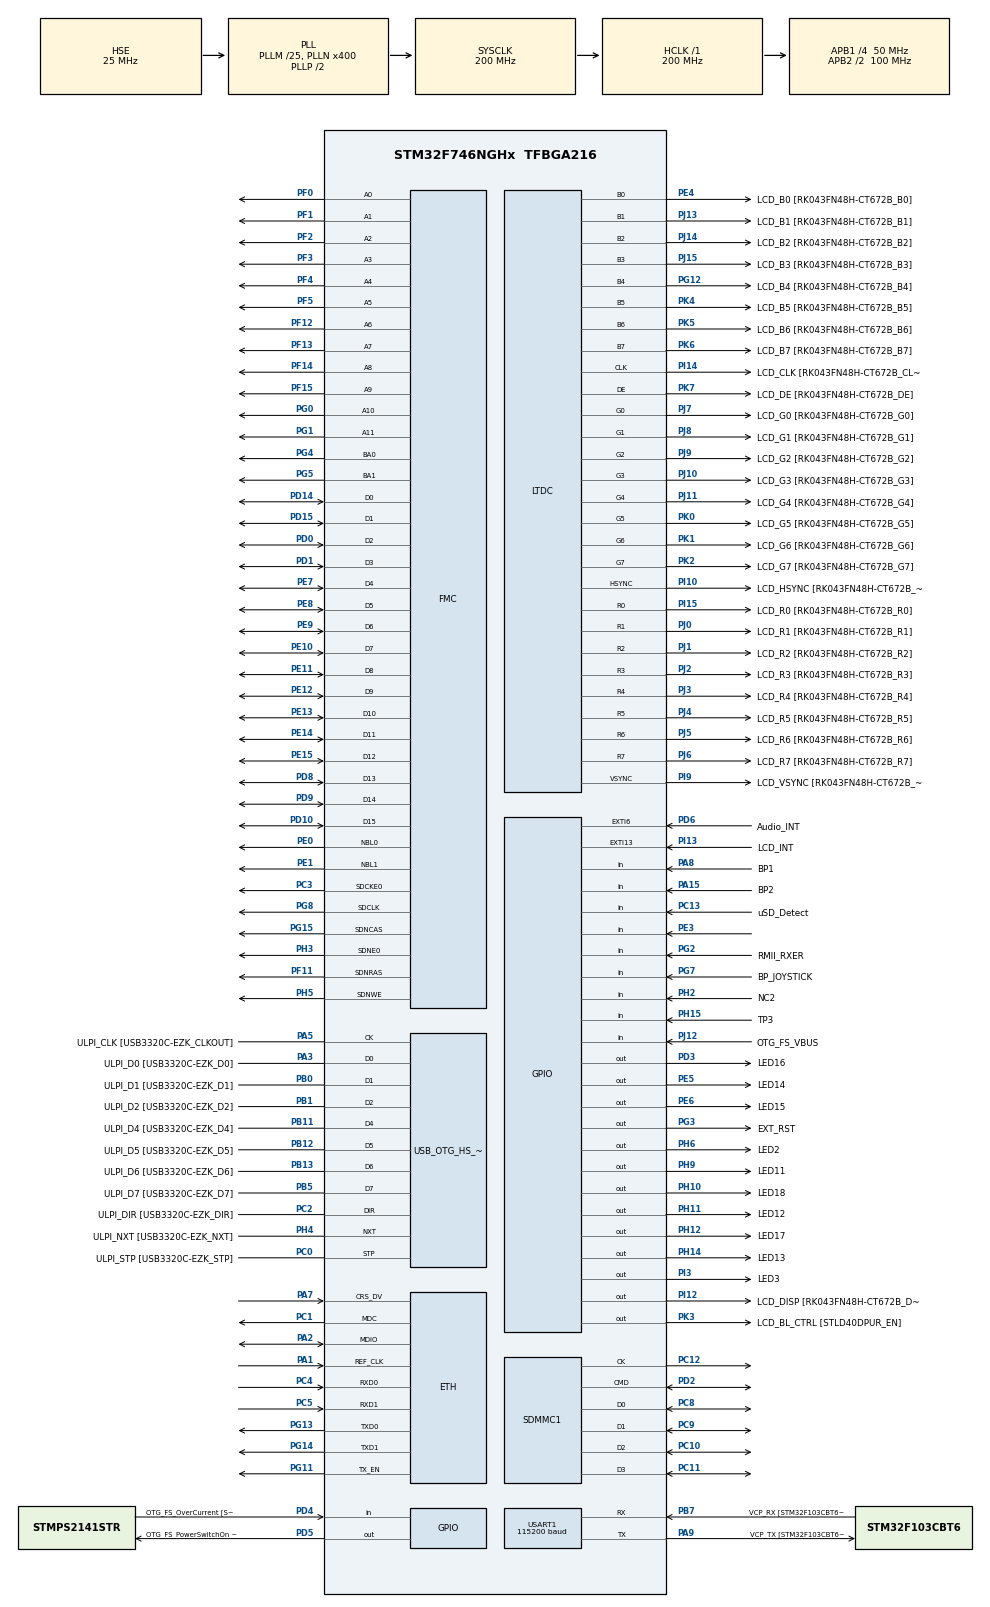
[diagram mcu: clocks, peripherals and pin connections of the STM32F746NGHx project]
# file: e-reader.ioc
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SH.FMC_A0.0=FMC_A0,12b-sda1
FATFS0.BSP.api=Unknown
PH15.GPIO_Label=TP3
NVIC.TIM6_DAC_IRQn=true\:0\:0\:false\:false\:true\:false\:false\:true
PG8.Signal=FMC_SDCLK
PG0.Signal=FMC_A10
PI15.GPIO_Label=LCD_R0 [RK043FN48H-CT672B_R0]
PK1.Signal=LTDC_G6
SH.FMC_D5_DA5.0=FMC_D5,sd-16b-d1
SH.FMC_D9_DA9.0=FMC_D9,sd-16b-d1
PF7.Signal=UART7_TX
RCC.PLL48CLockSelection=RCC_CLK48SOURCE_PLLSAIP
SH.FMC_SDNWE.0=FMC_SDNWE,12b-sda1
PH9.Signal=GPIO_Output
SH.FMC_D11_DA11.0=FMC_D11,sd-16b-d1
PJ5.Mode=RGB888
RCC.APB2TimFreq_Value=200000000
PC7.Signal=USART6_RX
PD0.Signal=FMC_D2_DA2
PD8.Signal=FMC_D13_DA13
PE1.Signal=FMC_NBL1
FATFS0.BSP.ip=GPIO
PK4.GPIO_Label=LCD_B5 [RK043FN48H-CT672B_B5]
PB12.GPIO_Label=ULPI_D5 [USB3320C-EZK_D5]
PJ14.Mode=RGB888
PG14.Mode=RMII
LTDC.PixelFormat_L0=LTDC_PIXEL_FORMAT_RGB565
PE9.Signal=FMC_D6_DA6
SH.FMC_A2.0=FMC_A2,12b-sda1
PB1.GPIO_Label=ULPI_D2 [USB3320C-EZK_D2]
PE4.GPIO_Label=LCD_B0 [RK043FN48H-CT672B_B0]
PC9.Mode=SD_4_bits_Wide_bus
PA8.Signal=GPIO_Input
SH.FMC_D1_DA1.0=FMC_D1,sd-16b-d1
VP_FREERTOS_VS_CMSIS_V1.Mode=CMSIS_V1
LTDC.HSync=41
PJ14.Signal=LTDC_B2
PB9.Signal=I2C1_SDA
Mcu.Package=TFBGA216
PB1.Signal=USB_OTG_HS_ULPI_D2
NVIC.TimeBase=TIM6_DAC_IRQn
NVIC.TimeBaseIP=TIM6
PB9.GPIO_PuPd=GPIO_NOPULL
PC11.Mode=SD_4_bits_Wide_bus
RCC.APB2CLKDivider=RCC_HCLK_DIV2
LTDC.VSync=10
RCC.APB1TimFreq_Value=100000000
PC14/OSC32_IN.GPIO_Label=RCC_OSC32_IN
PB13.Mode=Host_HS
PJ13.Mode=RGB888
Dma.SDMMC1_RX.0.Mode=DMA_PFCTRL
PD15.Signal=FMC_D1_DA1
PJ1.GPIO_Label=LCD_R2 [RK043FN48H-CT672B_R2]
PG12.Signal=LTDC_B4
PA5.Mode=Host_HS
FATFS0.BSP.STBoard=false
PK4.Signal=LTDC_B5
SH.FMC_A4.0=FMC_A4,12b-sda1
FREERTOS.Tasks01=defaultTask,0,1024,StartDefaultTask,Default,NULL,Dynamic,NULL,NULL;displayer_task,0,2048,displayer_task_fn,Default,NULL,Dynamic,NULL,NULL;logic_task,1,1024,logic_task_fn,Default,NULL,Dynamic,NULL,NULL
Dma.SDMMC1_RX.0.PeriphInc=DMA_PINC_DISABLE
PI13.GPIO_ModeDefaultEXTI=GPIO_MODE_EVT_RISING
PG5.Signal=FMC_A15_BA1
PC13.Signal=GPIO_Input
SH.FMC_D10_DA10.0=FMC_D10,sd-16b-d1
FATFS0.BSP.mode=Input
FREERTOS.INCLUDE_vTaskDelayUntil=1
PD3.Signal=GPIO_Output
PI10.Mode=RGB888
PC2.Signal=USB_OTG_HS_ULPI_DIR
PI12.Signal=GPIO_Output
PJ11.Signal=LTDC_G4
RCC.PLLSAIRDiv=RCC_PLLSAIDIVR_8
LTDC.ImageWidth_L0=480
PD10.Signal=FMC_D15_DA15
PJ6.Mode=RGB888
PA3.Mode=Host_HS
PB8.GPIO_Label=ARDUINO SCL/D15
PJ8.GPIO_Label=LCD_G1 [RK043FN48H-CT672B_G1]
PJ3.Signal=LTDC_R4
PI8.GPIO_Label=NC1 [TP2]
PA8.GPIO_Label=BP1
PH11.GPIO_Label=LED12
LWIP.CHECKSUM_GEN_TCP=1
NVIC.DMA2_Stream6_IRQn=true\:5\:0\:false\:false\:true\:true\:false\:true
PJ11.GPIO_Label=LCD_G4 [RK043FN48H-CT672B_G4]
PB14.Signal=SPI2_MISO
PA5.Signal=USB_OTG_HS_ULPI_CK
PC12.Mode=SD_4_bits_Wide_bus
PJ4.GPIO_Label=LCD_R5 [RK043FN48H-CT672B_R5]
PK7.GPIO_Label=LCD_DE [RK043FN48H-CT672B_DE]
SH.FMC_A6.0=FMC_A6,12b-sda1
PE14.Signal=FMC_D11_DA11
PG7.GPIO_Label=BP_JOYSTICK
PI2.Signal=S_TIM8_CH4
PF13.Signal=FMC_A7
PJ15.GPIO_Label=LCD_B3 [RK043FN48H-CT672B_B3]
PC8.Mode=SD_4_bits_Wide_bus
PJ15.Mode=RGB888
ETH.MediaInterface=ETH_MEDIA_INTERFACE_RMII
PA5.GPIO_Label=ULPI_CLK [USB3320C-EZK_CLKOUT]
PK4.Mode=RGB888
PE5.GPIO_Label=LED14
Dma.SDMMC1_TX.1.PeriphDataAlignment=DMA_PDATAALIGN_WORD
PJ8.Signal=LTDC_G1
PJ0.GPIO_Label=LCD_R1 [RK043FN48H-CT672B_R1]
ProjectManager.HeapSize=0x400
PB1.Mode=Host_HS
PH6.Signal=GPIO_Output
FREERTOS.configUSE_RECURSIVE_MUTEXES=1
NVIC.PriorityGroup=NVIC_PRIORITYGROUP_4
PI1.GPIO_Mode=GPIO_MODE_AF_PP
PE3.Signal=GPIO_Input
PJ4.Mode=RGB888
PC15/OSC32_OUT.Signal=RCC_OSC32_OUT
PF4.Signal=FMC_A4
PD2.Signal=SDMMC1_CMD
FATFS0.BSP.name=Detect_SDIO
PC1.Mode=RMII
PI1.GPIO_Label=ARDUINO SCK/D13
Mcu.Family=STM32F7
LTDC.BlendingFactor1_L0=LTDC_BLENDING_FACTOR1_PAxCA
PK3.Signal=GPIO_Output
SH.FMC_A8.0=FMC_A8,12b-sda1
PC15/OSC32_OUT.GPIO_Label=RCC_OSC32_OUT
PH14.Signal=GPIO_Output
PH10.Signal=GPIO_Output
SH.FMC_D14_DA14.0=FMC_D14,sd-16b-d1
PG2.Signal=GPIO_Input
USART1.BaudRate=115200
PC14/OSC32_IN.Mode=LSE-External-Oscillator
SH.FMC_A14_BA0.0=FMC_BA0,FourSdramBanks1
SH.FMC_A11.0=FMC_A11,12b-sda1
Dma.SDMMC1_RX.0.Instance=DMA2_Stream3
Dma.SDMMC1_RX.0.FIFOMode=DMA_FIFOMODE_ENABLE
PB13.GPIO_Label=ULPI_D6 [USB3320C-EZK_D6]
PB15.Signal=SPI2_MOSI
PG15.Signal=FMC_SDNCAS
PG11.Signal=ETH_TX_EN
PJ5.GPIO_Label=LCD_R6 [RK043FN48H-CT672B_R6]
PJ14.GPIO_Label=LCD_B2 [RK043FN48H-CT672B_B2]
PA15.GPIO_Label=BP2
PJ2.Signal=LTDC_R3
SH.FMC_NBL1.0=FMC_NBL1,Sd2ByteEnable1
LTDC.WindowX1_L0=480
PI9.Mode=RGB888
PK2.Mode=RGB888
PA9.GPIO_Mode=GPIO_MODE_AF_PP
RCC.HSE_VALUE=25000000
LWIP.CHECKSUM_CHECK_TCP=1
PI14.Mode=RGB888
PA14.Mode=Serial_Wire
PH7.GPIO_Label=LCD_SCL [RK043FN48H-CT672B_SCL]
PJ7.GPIO_Label=LCD_G0 [RK043FN48H-CT672B_G0]
PF11.Signal=FMC_SDNRAS
PB5.Mode=Host_HS
ETH.RxMode=ETH_RXINTERRUPT_MODE
PJ12.GPIO_Label=OTG_FS_VBUS
PB7.Signal=USART1_RX
SH.S_TIM3_CH1.0=TIM3_CH1
PB7.GPIO_Label=VCP_RX [STM32F103CBT6_PA2]
PB12.Mode=Host_HS
LWIP.CHECKSUM_CHECK_IP=1
PD5.GPIO_Label=OTG_FS_PowerSwitchOn [STMPS2141STR_EN]
PA15.Signal=GPIO_Input
PF8.Signal=ADC3_IN6
PB5.GPIO_Label=ULPI_D7 [USB3320C-EZK_D7]
Dma.Request1=SDMMC1_TX
PD3.GPIO_Label=LED16
PC5.Signal=ETH_RXD1
PE7.Signal=FMC_D4_DA4
PD6.Signal=GPXTI6
Dma.Request0=SDMMC1_RX
Dma.SDMMC1_RX.0.MemDataAlignment=DMA_MDATAALIGN_WORD
PI15.Mode=RGB888
PB4.Signal=S_TIM3_CH1
PG2.GPIO_Label=RMII_RXER
PA3.Signal=USB_OTG_HS_ULPI_D0
PK1.Mode=RGB888
PK6.Signal=LTDC_B7
NVIC.LTDC_IRQn=true\:5\:0\:false\:false\:true\:true\:true\:true
LTDC.WindowY1_L0=272
PG7.Signal=GPIO_Input
PJ8.Mode=RGB888
PH12.GPIO_Label=LED17
PC11.Signal=SDMMC1_D3
PI14.Signal=LTDC_CLK
PC8.Signal=SDMMC1_D0
PC10.Mode=SD_4_bits_Wide_bus
PC2.Mode=Host_HS
PD9.Signal=FMC_D14_DA14
PA9.GPIO_PuPd=GPIO_NOPULL
FATFS0.BSP.instance=PC13
USART1.VirtualMode-Asynchronous=VM_ASYNC
PA13.Signal=SYS_JTMS-SWDIO
FREERTOS.configUSE_IDLE_HOOK=1
PA9.Mode=Asynchronous
SH.FMC_D13_DA13.0=FMC_D13,sd-16b-d1
PH8.Signal=I2C3_SDA
RCC.USBFreq_Value=48000000
PA1.Signal=ETH_REF_CLK
PD2.Mode=SD_4_bits_Wide_bus
PK5.Mode=RGB888
board=STM32F746G-DISCO
PG12.Mode=RGB888
RCC.VCOOutputFreq_Value=400000000
PI9.Signal=LTDC_VSYNC
PH4.GPIO_Label=ULPI_NXT [USB3320C-EZK_NXT]
PI13.GPIO_Label=LCD_INT
SH.FMC_D12_DA12.0=FMC_D12,sd-16b-d1
Dma.SDMMC1_RX.0.MemBurst=DMA_MBURST_INC4
PI1.GPIO_Speed=GPIO_SPEED_FREQ_LOW
PF1.Signal=FMC_A1
PJ0.Signal=LTDC_R1
PE0.Signal=FMC_NBL0
PE12.Signal=FMC_D9_DA9
RCC.SYSCLKFreq_VALUE=200000000
Dma.SDMMC1_TX.1.MemBurst=DMA_MBURST_INC4
PJ5.Signal=LTDC_R6
RCC.HSI_VALUE=16000000
PH0/OSC_IN.GPIO_Label=OSC_25M [NZ2520SB-25.00M_OUT]
RCC.PLLQ=9
PI3.GPIO_Label=LED3
PH3.Signal=FMC_SDNE0
RCC.PLLM=25
RCC.PLLN=400
PA9.GPIO_Speed=GPIO_SPEED_FREQ_LOW
PA2.Mode=RMII
PB8.GPIO_Speed=GPIO_SPEED_FREQ_LOW
PJ2.GPIO_Label=LCD_R3 [RK043FN48H-CT672B_R3]
VP_CRC_VS_CRC.Mode=CRC_Activate
LTDC.ImageHeight_L0=272
Dma.SDMMC1_TX.1.PeriphInc=DMA_PINC_DISABLE
RCC.PLLI2SN=100
PB12.Signal=USB_OTG_HS_ULPI_D5
PK1.GPIO_Label=LCD_G6 [RK043FN48H-CT672B_G6]
PJ13.Signal=LTDC_B1
PA3.GPIO_Label=ULPI_D0 [USB3320C-EZK_D0]
PI12.PinState=GPIO_PIN_SET
SH.FMC_D7_DA7.0=FMC_D7,sd-16b-d1
PK5.Signal=LTDC_B6
VP_SYS_VS_tim6.Mode=TIM6
PJ9.Mode=RGB888
PH12.Signal=GPIO_Output
Dma.SDMMC1_RX.0.MemInc=DMA_MINC_ENABLE
VP_FATFS_VS_SDIO.Mode=SDIO
PK0.Mode=RGB888
PG4.Signal=FMC_A14_BA0
PC12.Signal=SDMMC1_CK
PA14.GPIO_Label=SWCLK
PH6.GPIO_Label=LED2
PK6.GPIO_Label=LCD_B7 [RK043FN48H-CT672B_B7]
PJ6.GPIO_Label=LCD_R7 [RK043FN48H-CT672B_R7]
PC5.Mode=RMII
PB13.Signal=USB_OTG_HS_ULPI_D6
PD6.GPIO_Label=Audio_INT
PG13.Signal=ETH_TXD0
PE6.GPIO_Label=LED15
RCC.SYSCLKSource=RCC_SYSCLKSOURCE_PLLCLK
PJ10.Signal=LTDC_G3
SH.FMC_A15_BA1.0=FMC_BA1,FourSdramBanks1
LWIP.NETMASK_ADDRESS=255.255.255.000
NVIC.SDMMC1_IRQn=true\:5\:0\:false\:false\:true\:true\:true\:true
PB7.GPIO_Mode=GPIO_MODE_AF_PP
PJ13.GPIO_Label=LCD_B1 [RK043FN48H-CT672B_B1]
PH5.Signal=FMC_SDNWE
LWIP.CHECKSUM_GEN_IP=1
PD4.Signal=GPIO_Input
PH1/OSC_OUT.Signal=RCC_OSC_OUT
PC3.Signal=FMC_SDCKE0
PE5.Signal=GPIO_Output
PH10.GPIO_Label=LED18
FATFS0.BSP.i2caddr=0
PK7.Mode=RGB888
PJ2.Mode=RGB888
PI3.Signal=GPIO_Output
PF3.Signal=FMC_A3
PE10.Signal=FMC_D7_DA7
RCC.SDMMCClockSelection=RCC_SDMMC1CLKSOURCE_CLK48
SH.S_TIM8_CH4.0=TIM8_CH4
PD6.GPIO_ModeDefaultEXTI=GPIO_MODE_EVT_RISING
FATFS0.BSP.solution=PC13
Dma.SDMMC1_RX.0.PeriphBurst=DMA_PBURST_INC4
PJ4.Signal=LTDC_R5
SH.FMC_A1.0=FMC_A1,12b-sda1
PH2.Signal=GPIO_Input
SH.FMC_SDCLK.0=FMC_SDCLK,12b-sda1
PF14.Signal=FMC_A8
VP_DMA2D_VS_DMA2D.Mode=DMA2D_Activate
Dma.SDMMC1_TX.1.MemInc=DMA_MINC_ENABLE
PJ1.Mode=RGB888
SH.FMC_D3_DA3.0=FMC_D3,sd-16b-d1
PC4.Mode=RMII
LWIP.IP_ADDRESS=192.168.137.101
PI10.GPIO_Label=LCD_HSYNC [RK043FN48H-CT672B_HSYNC]
PB7.GPIO_PuPd=GPIO_NOPULL
Dma.SDMMC1_TX.1.Instance=DMA2_Stream6
PK3.PinState=GPIO_PIN_SET
PH15.Signal=GPIO_Input
PA9.GPIO_Label=VCP_TX [STM32F103CBT6_PA3]
FREERTOS.configCHECK_FOR_STACK_OVERFLOW=2
PB8.GPIO_PuPd=GPIO_NOPULL
PC6.Signal=USART6_TX
ETH.MACAddr=00\:80\:E1\:E0\:00\:00
PB11.GPIO_Label=ULPI_D4 [USB3320C-EZK_D4]
PD1.Signal=FMC_D3_DA3
Dma.SDMMC1_RX.0.PeriphDataAlignment=DMA_PDATAALIGN_WORD
LWIP.LWIP_DHCP=0
PC0.Signal=USB_OTG_HS_ULPI_STP
RCC.APB1CLKDivider=RCC_HCLK_DIV4
SH.FMC_A3.0=FMC_A3,12b-sda1
PJ7.Signal=LTDC_G0
PB11.Mode=Host_HS
SH.FMC_D15_DA15.0=FMC_D15,sd-16b-d1
PA9.Signal=USART1_TX
FATFS.BSP.number=1
PJ15.Signal=LTDC_B3
PH9.GPIO_Label=LED11
PI9.GPIO_Label=LCD_VSYNC [RK043FN48H-CT672B_VSYNC]
PA1.Mode=RMII
PE15.Signal=FMC_D12_DA12
PE8.Signal=FMC_D5_DA5
PI1.Signal=SPI2_SCK
Dma.SDMMC1_RX.0.Direction=DMA_PERIPH_TO_MEMORY
Dma.SDMMC1_TX.1.FIFOMode=DMA_FIFOMODE_ENABLE
SH.FMC_SDNCAS.0=FMC_SDNCAS,12b-sda1
PA13.Mode=Serial_Wire
PH4.Mode=Host_HS
PH14.GPIO_Label=LED13
PA4.Signal=COMP_DAC1_group
PB5.Signal=USB_OTG_HS_ULPI_D7
FREERTOS.configUSE_COUNTING_SEMAPHORES=1
PG11.Mode=RMII
SH.FMC_A5.0=FMC_A5,12b-sda1
LTDC.Alpha_L0=255
PK3.GPIO_Label=LCD_BL_CTRL [STLD40DPUR_EN]
LWIP.Version=v2.1.2_Cube
PF9.Signal=ADC3_IN7
PJ10.Mode=RGB888
PG3.GPIO_Label=EXT_RST
PB0.Signal=USB_OTG_HS_ULPI_D1
PC1.Signal=ETH_MDC
PH2.GPIO_Label=NC2
PC3.Mode=SdramChipSelect1_1
PK7.Signal=LTDC_DE
RCC.CortexFreq_Value=200000000
LTDC.HBP=13
PC10.Signal=SDMMC1_D2
SH.FMC_NBL0.0=FMC_NBL0,Sd2ByteEnable1
PC0.GPIO_Label=ULPI_STP [USB3320C-EZK_STP]
SH.FMC_D6_DA6.0=FMC_D6,sd-16b-d1
PA0/WKUP.Signal=ADCx_IN0
PB0.GPIO_Label=ULPI_D1 [USB3320C-EZK_D1]
Dma.SDMMC1_RX.0.Priority=DMA_PRIORITY_LOW
PC13.GPIO_Label=uSD_Detect
PK5.GPIO_Label=LCD_B6 [RK043FN48H-CT672B_B6]
PB11.Signal=USB_OTG_HS_ULPI_D4
PI14.GPIO_Label=LCD_CLK [RK043FN48H-CT672B_CLK]
ProjectManager.StackSize=0x800
PH3.Mode=SdramChipSelect1_1
Dma.SDMMC1_TX.1.FIFOThreshold=DMA_FIFO_THRESHOLD_FULL
PJ6.Signal=LTDC_R7
SH.FMC_A7.0=FMC_A7,12b-sda1
PH0/OSC_IN.Mode=HSE-External-Oscillator
RCC.HCLKFreq_Value=200000000
PF12.Signal=FMC_A6
FREERTOS.configUSE_MALLOC_FAILED_HOOK=1
PI13.Signal=GPXTI13
SH.FMC_A10.0=FMC_A10,12b-sda1
RCC.AHBFreq_Value=200000000
NVIC.ETH_IRQn=true\:5\:0\:false\:false\:true\:true\:false\:true
SH.FMC_D8_DA8.0=FMC_D8,sd-16b-d1
PI8.Signal=RTC_TS
SH.FMC_D2_DA2.0=FMC_D2,sd-16b-d1
PE13.Signal=FMC_D10_DA10
PI1.GPIO_PuPd=GPIO_NOPULL
PK6.Mode=RGB888
PI0.Signal=SPI2_NSS
LTDC.HFP=32
LTDC.BlendingFactor2_L0=LTDC_BLENDING_FACTOR2_PAxCA
PG13.Mode=RMII
SH.ADCx_IN0.0=ADC1_IN0
PE4.Mode=RGB888
SH.FMC_SDNRAS.0=FMC_SDNRAS,12b-sda1
LTDC.ActiveW=480
PE4.Signal=LTDC_B0
PH1/OSC_OUT.Mode=HSE-External-Oscillator
FREERTOS.configTOTAL_HEAP_SIZE=32768
PJ0.Mode=RGB888
PJ9.Signal=LTDC_G2
SH.FMC_D0_DA0.0=FMC_D0,sd-16b-d1
PJ12.Signal=GPIO_Input
PC14/OSC32_IN.Signal=RCC_OSC32_IN
PK0.GPIO_Label=LCD_G5 [RK043FN48H-CT672B_G5]
SH.FMC_A9.0=FMC_A9,12b-sda1
PJ1.Signal=LTDC_R2
SH.FMC_D4_DA4.0=FMC_D4,sd-16b-d1
PI12.GPIO_Label=LCD_DISP [RK043FN48H-CT672B_DISP] 
RCC.PLLSAIN=384
PF5.Signal=FMC_A5
RCC.PLLSAIP=RCC_PLLSAIP_DIV8
RCC.PLLSAIR=5
PH7.Signal=I2C3_SCL
PB9.GPIO_Speed=GPIO_SPEED_FREQ_LOW
PJ3.GPIO_Label=LCD_R4 [RK043FN48H-CT672B_R4]
PK2.GPIO_Label=LCD_G7 [RK043FN48H-CT672B_G7]
PJ7.Mode=RGB888
PF0.Signal=FMC_A0
PC2.GPIO_Label=ULPI_DIR [USB3320C-EZK_DIR]
Dma.SDMMC1_TX.1.Direction=DMA_MEMORY_TO_PERIPH
PB7.GPIO_Speed=GPIO_SPEED_FREQ_LOW
RCC.PLLSourceVirtual=RCC_PLLSOURCE_HSE
SH.COMP_DAC1_group.0=DAC_OUT1
PK2.Signal=LTDC_G7
LTDC.FBStartAdress_L0=0xC0000000
PA7.Mode=RMII
PB9.GPIO_Label=ARDUINO SDA/D14
PH11.Signal=GPIO_Output
PG3.Signal=GPIO_Output
PG1.Signal=FMC_A11
PC4.Signal=ETH_RXD0
PI10.Signal=LTDC_HSYNC
PD5.Signal=GPIO_Output
FREERTOS.configUSE_APPLICATION_TASK_TAG=1
ETH.PhyAddress=0
VP_LWIP_VS_Enabled.Mode=Enabled
LWIP.GATEWAY_ADDRESS=192.168.137.001
PC0.Mode=Host_HS
PJ11.Mode=RGB888
PH8.GPIO_Label=LCD_SDA [RK043FN48H-CT672B_SDA]
Dma.SDMMC1_TX.1.PeriphBurst=DMA_PBURST_INC4
PH4.Signal=USB_OTG_HS_ULPI_NXT
ProjectManager.TargetToolchain=STM32CubeIDE
LTDC.ActiveH=272
PJ9.GPIO_Label=LCD_G2 [RK043FN48H-CT672B_G2]
PF2.Signal=FMC_A2
NVIC.DMA2_Stream3_IRQn=true\:5\:0\:false\:false\:true\:true\:false\:true
PE11.Signal=FMC_D8_DA8
PK0.Signal=LTDC_G5
PG14.Signal=ETH_TXD1
PJ10.GPIO_Label=LCD_G3 [RK043FN48H-CT672B_G3]
PB0.Mode=Host_HS
PB9.GPIO_Mode=GPIO_MODE_AF_OD
PJ3.Mode=RGB888
PH0/OSC_IN.Signal=RCC_OSC_IN
RCC.APB2Freq_Value=100000000
LTDC.Layers=0
PD4.GPIO_Label=OTG_FS_OverCurrent [STMPS2141STR_Fault]
PF10.Signal=ADC3_IN8
PF15.Signal=FMC_A9
Dma.SDMMC1_TX.1.Priority=DMA_PRIORITY_LOW
PD5.PinState=GPIO_PIN_SET
PE6.Signal=GPIO_Output
Mcu.Name=STM32F746NGHx
PA13.GPIO_Label=SWDIO
PA2.Signal=ETH_MDIO
PD14.Signal=FMC_D0_DA0
Dma.SDMMC1_RX.0.FIFOThreshold=DMA_FIFO_THRESHOLD_FULL
PC15/OSC32_OUT.Mode=LSE-External-Oscillator
PB7.Mode=Asynchronous
PA14.Signal=SYS_JTCK-SWCLK
PG12.GPIO_Label=LCD_B4 [RK043FN48H-CT672B_B4]
Dma.SDMMC1_TX.1.MemDataAlignment=DMA_MDATAALIGN_WORD
PK3.GPIO_Speed=GPIO_SPEED_FREQ_LOW
PI15.Signal=LTDC_R0
PB8.Signal=I2C1_SCL
PC9.Signal=SDMMC1_D1
PB8.GPIO_Mode=GPIO_MODE_AF_OD
RCC.APB1Freq_Value=50000000
Dma.SDMMC1_TX.1.Mode=DMA_PFCTRL
PA7.Signal=ETH_CRS_DV

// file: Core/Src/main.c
/* USER CODE BEGIN Header */
/**
  ******************************************************************************
  * @file           : main.c
  * @brief          : Main program body
  ******************************************************************************
  * @attention
  *
  * <h2><center>&copy; Copyright (c) 2021 STMicroelectronics.
  * All rights reserved.</center></h2>
  *
  * This software component is licensed by ST under Ultimate Liberty license
  * SLA0044, the "License"; You may not use this file except in compliance with
  * the License. You may obtain a copy of the License at:
  *                             www.st.com/SLA0044
  *
  ******************************************************************************
  */
/* USER CODE END Header */
#include "main.h"
#include "cmsis_os.h"
#include "fatfs.h"
#include "lwip.h"

/* USER CODE BEGIN Includes */

#include "global.h"

/* USER CODE END Includes */

CRC_HandleTypeDef hcrc;

DMA2D_HandleTypeDef hdma2d;

LTDC_HandleTypeDef hltdc;

SD_HandleTypeDef hsd1;
DMA_HandleTypeDef hdma_sdmmc1_rx;
DMA_HandleTypeDef hdma_sdmmc1_tx;

UART_HandleTypeDef huart1;

SDRAM_HandleTypeDef hsdram1;

osThreadId defaultTaskHandle;
osThreadId displayer_taskHandle;
osThreadId logic_taskHandle;

void SystemClock_Config(void);
static void MX_GPIO_Init(void);
static void MX_DMA_Init(void);
static void MX_LTDC_Init(void);
static void MX_USART1_UART_Init(void);
static void MX_FMC_Init(void);
static void MX_DMA2D_Init(void);
static void MX_CRC_Init(void);
static void MX_SDMMC1_SD_Init(void);
void StartDefaultTask(void const * argument);
void displayer_task_fn(void const * argument);
void logic_task_fn(void const * argument);

int main(void)
{

  /* MCU Configuration--------------------------------------------------------*/

  /* Reset of all peripherals, Initializes the Flash interface and the Systick. */
  HAL_Init();

  /* Configure the system clock */
  SystemClock_Config();

  /* Initialize all configured peripherals */
  MX_GPIO_Init();
  MX_DMA_Init();
  MX_LTDC_Init();
  MX_USART1_UART_Init();
  MX_FMC_Init();
  MX_DMA2D_Init();
  MX_CRC_Init();
  MX_SDMMC1_SD_Init();
  MX_FATFS_Init();

  /* Create the thread(s) */
  /* definition and creation of defaultTask */
  osThreadDef(defaultTask, StartDefaultTask, osPriorityNormal, 0, 1024);
  defaultTaskHandle = osThreadCreate(osThread(defaultTask), NULL);

  /* definition and creation of displayer_task */
  osThreadDef(displayer_task, displayer_task_fn, osPriorityNormal, 0, 2048);
  displayer_taskHandle = osThreadCreate(osThread(displayer_task), NULL);

  /* definition and creation of logic_task */
  osThreadDef(logic_task, logic_task_fn, osPriorityAboveNormal, 0, 1024);
  logic_taskHandle = osThreadCreate(osThread(logic_task), NULL);

  /* Start scheduler */
  osKernelStart();

  /* We should never get here as control is now taken by the scheduler */
  /* Infinite loop */
  while (1)
  {

  }
}

void SystemClock_Config(void)
{
  RCC_OscInitTypeDef RCC_OscInitStruct = {0};
  RCC_ClkInitTypeDef RCC_ClkInitStruct = {0};
  RCC_PeriphCLKInitTypeDef PeriphClkInitStruct = {0};

  /** Configure LSE Drive Capability
  */
  HAL_PWR_EnableBkUpAccess();
  /** Configure the main internal regulator output voltage
  */
  __HAL_RCC_PWR_CLK_ENABLE();
  __HAL_PWR_VOLTAGESCALING_CONFIG(PWR_REGULATOR_VOLTAGE_SCALE1);
  /** Initializes the RCC Oscillators according to the specified parameters
  * in the RCC_OscInitTypeDef structure.
  */
  RCC_OscInitStruct.OscillatorType = RCC_OSCILLATORTYPE_HSE;
  RCC_OscInitStruct.HSEState = RCC_HSE_ON;
  RCC_OscInitStruct.PLL.PLLState = RCC_PLL_ON;
  RCC_OscInitStruct.PLL.PLLSource = RCC_PLLSOURCE_HSE;
  RCC_OscInitStruct.PLL.PLLM = 25;
  RCC_OscInitStruct.PLL.PLLN = 400;
  RCC_OscInitStruct.PLL.PLLP = RCC_PLLP_DIV2;
  RCC_OscInitStruct.PLL.PLLQ = 9;
  if (HAL_RCC_OscConfig(&RCC_OscInitStruct) != HAL_OK)
  {
    Error_Handler();
  }
  /** Activate the Over-Drive mode
  */
  if (HAL_PWREx_EnableOverDrive() != HAL_OK)
  {
    Error_Handler();
  }
  /** Initializes the CPU, AHB and APB buses clocks
  */
  RCC_ClkInitStruct.ClockType = RCC_CLOCKTYPE_HCLK|RCC_CLOCKTYPE_SYSCLK
                              |RCC_CLOCKTYPE_PCLK1|RCC_CLOCKTYPE_PCLK2;
  RCC_ClkInitStruct.SYSCLKSource = RCC_SYSCLKSOURCE_PLLCLK;
  RCC_ClkInitStruct.AHBCLKDivider = RCC_SYSCLK_DIV1;
  RCC_ClkInitStruct.APB1CLKDivider = RCC_HCLK_DIV4;
  RCC_ClkInitStruct.APB2CLKDivider = RCC_HCLK_DIV2;

  if (HAL_RCC_ClockConfig(&RCC_ClkInitStruct, FLASH_LATENCY_6) != HAL_OK)
  {
    Error_Handler();
  }
  PeriphClkInitStruct.PeriphClockSelection = RCC_PERIPHCLK_LTDC|RCC_PERIPHCLK_USART1
                              |RCC_PERIPHCLK_SDMMC1|RCC_PERIPHCLK_CLK48;
  PeriphClkInitStruct.PLLSAI.PLLSAIN = 384;
  PeriphClkInitStruct.PLLSAI.PLLSAIR = 5;
  PeriphClkInitStruct.PLLSAI.PLLSAIQ = 2;
  PeriphClkInitStruct.PLLSAI.PLLSAIP = RCC_PLLSAIP_DIV8;
  PeriphClkInitStruct.PLLSAIDivQ = 1;
  PeriphClkInitStruct.PLLSAIDivR = RCC_PLLSAIDIVR_8;
  PeriphClkInitStruct.Usart1ClockSelection = RCC_USART1CLKSOURCE_PCLK2;
  PeriphClkInitStruct.Clk48ClockSelection = RCC_CLK48SOURCE_PLLSAIP;
  PeriphClkInitStruct.Sdmmc1ClockSelection = RCC_SDMMC1CLKSOURCE_CLK48;
  if (HAL_RCCEx_PeriphCLKConfig(&PeriphClkInitStruct) != HAL_OK)
  {
    Error_Handler();
  }
}

static void MX_CRC_Init(void)
{

  hcrc.Instance = CRC;
  hcrc.Init.DefaultPolynomialUse = DEFAULT_POLYNOMIAL_ENABLE;
  hcrc.Init.DefaultInitValueUse = DEFAULT_INIT_VALUE_ENABLE;
  hcrc.Init.InputDataInversionMode = CRC_INPUTDATA_INVERSION_NONE;
  hcrc.Init.OutputDataInversionMode = CRC_OUTPUTDATA_INVERSION_DISABLE;
  hcrc.InputDataFormat = CRC_INPUTDATA_FORMAT_BYTES;
  if (HAL_CRC_Init(&hcrc) != HAL_OK)
  {
    Error_Handler();
  }

}

static void MX_DMA2D_Init(void)
{

  hdma2d.Instance = DMA2D;
  hdma2d.Init.Mode = DMA2D_M2M;
  hdma2d.Init.ColorMode = DMA2D_OUTPUT_ARGB8888;
  hdma2d.Init.OutputOffset = 0;
  hdma2d.LayerCfg[1].InputOffset = 0;
  hdma2d.LayerCfg[1].InputColorMode = DMA2D_INPUT_ARGB8888;
  hdma2d.LayerCfg[1].AlphaMode = DMA2D_NO_MODIF_ALPHA;
  hdma2d.LayerCfg[1].InputAlpha = 0;
  if (HAL_DMA2D_Init(&hdma2d) != HAL_OK)
  {
    Error_Handler();
  }
  if (HAL_DMA2D_ConfigLayer(&hdma2d, 1) != HAL_OK)
  {
    Error_Handler();
  }

}

static void MX_LTDC_Init(void)
{

  LTDC_LayerCfgTypeDef pLayerCfg = {0};

  hltdc.Instance = LTDC;
  hltdc.Init.HSPolarity = LTDC_HSPOLARITY_AL;
  hltdc.Init.VSPolarity = LTDC_VSPOLARITY_AL;
  hltdc.Init.DEPolarity = LTDC_DEPOLARITY_AL;
  hltdc.Init.PCPolarity = LTDC_PCPOLARITY_IPC;
  hltdc.Init.HorizontalSync = 40;
  hltdc.Init.VerticalSync = 9;
  hltdc.Init.AccumulatedHBP = 53;
  hltdc.Init.AccumulatedVBP = 11;
  hltdc.Init.AccumulatedActiveW = 533;
  hltdc.Init.AccumulatedActiveH = 283;
  hltdc.Init.TotalWidth = 565;
  hltdc.Init.TotalHeigh = 285;
  hltdc.Init.Backcolor.Blue = 0;
  hltdc.Init.Backcolor.Green = 0;
  hltdc.Init.Backcolor.Red = 0;
  if (HAL_LTDC_Init(&hltdc) != HAL_OK)
  {
    Error_Handler();
  }
  pLayerCfg.WindowX0 = 0;
  pLayerCfg.WindowX1 = 480;
  pLayerCfg.WindowY0 = 0;
  pLayerCfg.WindowY1 = 272;
  pLayerCfg.PixelFormat = LTDC_PIXEL_FORMAT_RGB565;
  pLayerCfg.Alpha = 255;
  pLayerCfg.Alpha0 = 0;
  pLayerCfg.BlendingFactor1 = LTDC_BLENDING_FACTOR1_PAxCA;
  pLayerCfg.BlendingFactor2 = LTDC_BLENDING_FACTOR2_PAxCA;
  pLayerCfg.FBStartAdress = 0xC0000000;
  pLayerCfg.ImageWidth = 480;
  pLayerCfg.ImageHeight = 272;
  pLayerCfg.Backcolor.Blue = 0;
  pLayerCfg.Backcolor.Green = 0;
  pLayerCfg.Backcolor.Red = 0;
  if (HAL_LTDC_ConfigLayer(&hltdc, &pLayerCfg, 0) != HAL_OK)
  {
    Error_Handler();
  }

}

static void MX_SDMMC1_SD_Init(void)
{

  hsd1.Instance = SDMMC1;
  hsd1.Init.ClockEdge = SDMMC_CLOCK_EDGE_RISING;
  hsd1.Init.ClockBypass = SDMMC_CLOCK_BYPASS_DISABLE;
  hsd1.Init.ClockPowerSave = SDMMC_CLOCK_POWER_SAVE_DISABLE;
  hsd1.Init.BusWide = SDMMC_BUS_WIDE_1B;
  hsd1.Init.HardwareFlowControl = SDMMC_HARDWARE_FLOW_CONTROL_DISABLE;
  hsd1.Init.ClockDiv = 0;

}

static void MX_USART1_UART_Init(void)
{

  huart1.Instance = USART1;
  huart1.Init.BaudRate = 115200;
  huart1.Init.WordLength = UART_WORDLENGTH_8B;
  huart1.Init.StopBits = UART_STOPBITS_1;
  huart1.Init.Parity = UART_PARITY_NONE;
  huart1.Init.Mode = UART_MODE_TX_RX;
  huart1.Init.HwFlowCtl = UART_HWCONTROL_NONE;
  huart1.Init.OverSampling = UART_OVERSAMPLING_16;
  huart1.Init.OneBitSampling = UART_ONE_BIT_SAMPLE_DISABLE;
  huart1.AdvancedInit.AdvFeatureInit = UART_ADVFEATURE_NO_INIT;
  if (HAL_UART_Init(&huart1) != HAL_OK)
  {
    Error_Handler();
  }

}

static void MX_DMA_Init(void)
{

  /* DMA controller clock enable */
  __HAL_RCC_DMA2_CLK_ENABLE();

  /* DMA interrupt init */
  /* DMA2_Stream3_IRQn interrupt configuration */
  HAL_NVIC_SetPriority(DMA2_Stream3_IRQn, 5, 0);
  HAL_NVIC_EnableIRQ(DMA2_Stream3_IRQn);
  /* DMA2_Stream6_IRQn interrupt configuration */
  HAL_NVIC_SetPriority(DMA2_Stream6_IRQn, 5, 0);
  HAL_NVIC_EnableIRQ(DMA2_Stream6_IRQn);

}

/* FMC initialization function */
static void MX_FMC_Init(void)
{

  FMC_SDRAM_TimingTypeDef SdramTiming = {0};

  /** Perform the SDRAM1 memory initialization sequence
  */
  hsdram1.Instance = FMC_SDRAM_DEVICE;
  /* hsdram1.Init */
  hsdram1.Init.SDBank = FMC_SDRAM_BANK1;
  hsdram1.Init.ColumnBitsNumber = FMC_SDRAM_COLUMN_BITS_NUM_8;
  hsdram1.Init.RowBitsNumber = FMC_SDRAM_ROW_BITS_NUM_12;
  hsdram1.Init.MemoryDataWidth = FMC_SDRAM_MEM_BUS_WIDTH_16;
  hsdram1.Init.InternalBankNumber = FMC_SDRAM_INTERN_BANKS_NUM_4;
  hsdram1.Init.CASLatency = FMC_SDRAM_CAS_LATENCY_1;
  hsdram1.Init.WriteProtection = FMC_SDRAM_WRITE_PROTECTION_DISABLE;
  hsdram1.Init.SDClockPeriod = FMC_SDRAM_CLOCK_DISABLE;
  hsdram1.Init.ReadBurst = FMC_SDRAM_RBURST_DISABLE;
  hsdram1.Init.ReadPipeDelay = FMC_SDRAM_RPIPE_DELAY_0;
  /* SdramTiming */
  SdramTiming.LoadToActiveDelay = 16;
  SdramTiming.ExitSelfRefreshDelay = 16;
  SdramTiming.SelfRefreshTime = 16;
  SdramTiming.RowCycleDelay = 16;
  SdramTiming.WriteRecoveryTime = 16;
  SdramTiming.RPDelay = 16;
  SdramTiming.RCDDelay = 16;

  if (HAL_SDRAM_Init(&hsdram1, &SdramTiming) != HAL_OK)
  {
    Error_Handler( );
  }

}

static void MX_GPIO_Init(void)
{
  GPIO_InitTypeDef GPIO_InitStruct = {0};

  /* GPIO Ports Clock Enable */
  __HAL_RCC_GPIOE_CLK_ENABLE();
  __HAL_RCC_GPIOG_CLK_ENABLE();
  __HAL_RCC_GPIOB_CLK_ENABLE();
  __HAL_RCC_GPIOC_CLK_ENABLE();
  __HAL_RCC_GPIOA_CLK_ENABLE();
  __HAL_RCC_GPIOJ_CLK_ENABLE();
  __HAL_RCC_GPIOD_CLK_ENABLE();
  __HAL_RCC_GPIOI_CLK_ENABLE();
  __HAL_RCC_GPIOK_CLK_ENABLE();
  __HAL_RCC_GPIOF_CLK_ENABLE();
  __HAL_RCC_GPIOH_CLK_ENABLE();

  /*Configure GPIO pin Output Level */
  HAL_GPIO_WritePin(GPIOE, LED14_Pin|LED15_Pin, GPIO_PIN_RESET);

  /*Configure GPIO pin Output Level */
  HAL_GPIO_WritePin(OTG_FS_PowerSwitchOn_GPIO_Port, OTG_FS_PowerSwitchOn_Pin, GPIO_PIN_SET);

  /*Configure GPIO pin Output Level */
  HAL_GPIO_WritePin(LED16_GPIO_Port, LED16_Pin, GPIO_PIN_RESET);

  /*Configure GPIO pin Output Level */
  HAL_GPIO_WritePin(LED3_GPIO_Port, LED3_Pin, GPIO_PIN_RESET);

  /*Configure GPIO pin Output Level */
  HAL_GPIO_WritePin(LCD_BL_CTRL_GPIO_Port, LCD_BL_CTRL_Pin, GPIO_PIN_SET);

  /*Configure GPIO pin Output Level */
  HAL_GPIO_WritePin(LCD_DISP_GPIO_Port, LCD_DISP_Pin, GPIO_PIN_SET);

  /*Configure GPIO pin Output Level */
  HAL_GPIO_WritePin(GPIOH, LED13_Pin|LED17_Pin|LED11_Pin|LED12_Pin
                          |LED2_Pin|LED18_Pin, GPIO_PIN_RESET);

  /*Configure GPIO pin Output Level */
  HAL_GPIO_WritePin(EXT_RST_GPIO_Port, EXT_RST_Pin, GPIO_PIN_RESET);

  /*Configure GPIO pin : PE3 */
  GPIO_InitStruct.Pin = GPIO_PIN_3;
  GPIO_InitStruct.Mode = GPIO_MODE_INPUT;
  GPIO_InitStruct.Pull = GPIO_NOPULL;
  HAL_GPIO_Init(GPIOE, &GPIO_InitStruct);

  /*Configure GPIO pins : ARDUINO_SCL_D15_Pin ARDUINO_SDA_D14_Pin */
  GPIO_InitStruct.Pin = ARDUINO_SCL_D15_Pin|ARDUINO_SDA_D14_Pin;
  GPIO_InitStruct.Mode = GPIO_MODE_AF_OD;
  GPIO_InitStruct.Pull = GPIO_PULLUP;
  GPIO_InitStruct.Speed = GPIO_SPEED_FREQ_LOW;
  GPIO_InitStruct.Alternate = GPIO_AF4_I2C1;
  HAL_GPIO_Init(GPIOB, &GPIO_InitStruct);

  /*Configure GPIO pins : ULPI_D7_Pin ULPI_D6_Pin ULPI_D5_Pin ULPI_D2_Pin
                           ULPI_D1_Pin ULPI_D4_Pin */
  GPIO_InitStruct.Pin = ULPI_D7_Pin|ULPI_D6_Pin|ULPI_D5_Pin|ULPI_D2_Pin
                          |ULPI_D1_Pin|ULPI_D4_Pin;
  GPIO_InitStruct.Mode = GPIO_MODE_AF_PP;
  GPIO_InitStruct.Pull = GPIO_NOPULL;
  GPIO_InitStruct.Speed = GPIO_SPEED_FREQ_VERY_HIGH;
  GPIO_InitStruct.Alternate = GPIO_AF10_OTG_HS;
  HAL_GPIO_Init(GPIOB, &GPIO_InitStruct);

  /*Configure GPIO pin : PB4 */
  GPIO_InitStruct.Pin = GPIO_PIN_4;
  GPIO_InitStruct.Mode = GPIO_MODE_AF_PP;
  GPIO_InitStruct.Pull = GPIO_NOPULL;
  GPIO_InitStruct.Speed = GPIO_SPEED_FREQ_LOW;
  GPIO_InitStruct.Alternate = GPIO_AF2_TIM3;
  HAL_GPIO_Init(GPIOB, &GPIO_InitStruct);

  /*Configure GPIO pins : BP2_Pin BP1_Pin */
  GPIO_InitStruct.Pin = BP2_Pin|BP1_Pin;
  GPIO_InitStruct.Mode = GPIO_MODE_INPUT;
  GPIO_InitStruct.Pull = GPIO_NOPULL;
  HAL_GPIO_Init(GPIOA, &GPIO_InitStruct);

  /*Configure GPIO pins : LED14_Pin LED15_Pin */
  GPIO_InitStruct.Pin = LED14_Pin|LED15_Pin;
  GPIO_InitStruct.Mode = GPIO_MODE_OUTPUT_PP;
  GPIO_InitStruct.Pull = GPIO_NOPULL;
  GPIO_InitStruct.Speed = GPIO_SPEED_FREQ_LOW;
  HAL_GPIO_Init(GPIOE, &GPIO_InitStruct);

  /*Configure GPIO pin : OTG_FS_VBUS_Pin */
  GPIO_InitStruct.Pin = OTG_FS_VBUS_Pin;
  GPIO_InitStruct.Mode = GPIO_MODE_INPUT;
  GPIO_InitStruct.Pull = GPIO_NOPULL;
  HAL_GPIO_Init(OTG_FS_VBUS_GPIO_Port, &GPIO_InitStruct);

  /*Configure GPIO pin : Audio_INT_Pin */
  GPIO_InitStruct.Pin = Audio_INT_Pin;
  GPIO_InitStruct.Mode = GPIO_MODE_EVT_RISING;
  GPIO_InitStruct.Pull = GPIO_NOPULL;
  HAL_GPIO_Init(Audio_INT_GPIO_Port, &GPIO_InitStruct);

  /*Configure GPIO pins : OTG_FS_PowerSwitchOn_Pin LED16_Pin */
  GPIO_InitStruct.Pin = OTG_FS_PowerSwitchOn_Pin|LED16_Pin;
  GPIO_InitStruct.Mode = GPIO_MODE_OUTPUT_PP;
  GPIO_InitStruct.Pull = GPIO_NOPULL;
  GPIO_InitStruct.Speed = GPIO_SPEED_FREQ_LOW;
  HAL_GPIO_Init(GPIOD, &GPIO_InitStruct);

  /*Configure GPIO pins : LED3_Pin LCD_DISP_Pin */
  GPIO_InitStruct.Pin = LED3_Pin|LCD_DISP_Pin;
  GPIO_InitStruct.Mode = GPIO_MODE_OUTPUT_PP;
  GPIO_InitStruct.Pull = GPIO_NOPULL;
  GPIO_InitStruct.Speed = GPIO_SPEED_FREQ_LOW;
  HAL_GPIO_Init(GPIOI, &GPIO_InitStruct);

  /*Configure GPIO pin : PI2 */
  GPIO_InitStruct.Pin = GPIO_PIN_2;
  GPIO_InitStruct.Mode = GPIO_MODE_AF_PP;
  GPIO_InitStruct.Pull = GPIO_NOPULL;
  GPIO_InitStruct.Speed = GPIO_SPEED_FREQ_LOW;
  GPIO_InitStruct.Alternate = GPIO_AF3_TIM8;
  HAL_GPIO_Init(GPIOI, &GPIO_InitStruct);

  /*Configure GPIO pin : uSD_Detect_Pin */
  GPIO_InitStruct.Pin = uSD_Detect_Pin;
  GPIO_InitStruct.Mode = GPIO_MODE_INPUT;
  GPIO_InitStruct.Pull = GPIO_NOPULL;
  HAL_GPIO_Init(uSD_Detect_GPIO_Port, &GPIO_InitStruct);

  /*Configure GPIO pin : LCD_BL_CTRL_Pin */
  GPIO_InitStruct.Pin = LCD_BL_CTRL_Pin;
  GPIO_InitStruct.Mode = GPIO_MODE_OUTPUT_PP;
  GPIO_InitStruct.Pull = GPIO_NOPULL;
  GPIO_InitStruct.Speed = GPIO_SPEED_FREQ_LOW;
  HAL_GPIO_Init(LCD_BL_CTRL_GPIO_Port, &GPIO_InitStruct);

  /*Configure GPIO pin : OTG_FS_OverCurrent_Pin */
  GPIO_InitStruct.Pin = OTG_FS_OverCurrent_Pin;
  GPIO_InitStruct.Mode = GPIO_MODE_INPUT;
  GPIO_InitStruct.Pull = GPIO_NOPULL;
  HAL_GPIO_Init(OTG_FS_OverCurrent_GPIO_Port, &GPIO_InitStruct);

  /*Configure GPIO pins : TP3_Pin NC2_Pin */
  GPIO_InitStruct.Pin = TP3_Pin|NC2_Pin;
  GPIO_InitStruct.Mode = GPIO_MODE_INPUT;
  GPIO_InitStruct.Pull = GPIO_NOPULL;
  HAL_GPIO_Init(GPIOH, &GPIO_InitStruct);

  /*Configure GPIO pin : ARDUINO_SCK_D13_Pin */
  GPIO_InitStruct.Pin = ARDUINO_SCK_D13_Pin;
  GPIO_InitStruct.Mode = GPIO_MODE_AF_PP;
  GPIO_InitStruct.Pull = GPIO_NOPULL;
  GPIO_InitStruct.Speed = GPIO_SPEED_FREQ_LOW;
  GPIO_InitStruct.Alternate = GPIO_AF5_SPI2;
  HAL_GPIO_Init(ARDUINO_SCK_D13_GPIO_Port, &GPIO_InitStruct);

  /*Configure GPIO pins : LED13_Pin LED17_Pin LED11_Pin LED12_Pin
                           LED2_Pin LED18_Pin */
  GPIO_InitStruct.Pin = LED13_Pin|LED17_Pin|LED11_Pin|LED12_Pin
                          |LED2_Pin|LED18_Pin;
  GPIO_InitStruct.Mode = GPIO_MODE_OUTPUT_PP;
  GPIO_InitStruct.Pull = GPIO_NOPULL;
  GPIO_InitStruct.Speed = GPIO_SPEED_FREQ_LOW;
  HAL_GPIO_Init(GPIOH, &GPIO_InitStruct);

  /*Configure GPIO pin : PI0 */
  GPIO_InitStruct.Pin = GPIO_PIN_0;
  GPIO_InitStruct.Mode = GPIO_MODE_AF_PP;
  GPIO_InitStruct.Pull = GPIO_NOPULL;
  GPIO_InitStruct.Speed = GPIO_SPEED_FREQ_VERY_HIGH;
  GPIO_InitStruct.Alternate = GPIO_AF5_SPI2;
  HAL_GPIO_Init(GPIOI, &GPIO_InitStruct);

  /*Configure GPIO pin : LCD_INT_Pin */
  GPIO_InitStruct.Pin = LCD_INT_Pin;
  GPIO_InitStruct.Mode = GPIO_MODE_EVT_RISING;
  GPIO_InitStruct.Pull = GPIO_NOPULL;
  HAL_GPIO_Init(LCD_INT_GPIO_Port, &GPIO_InitStruct);

  /*Configure GPIO pins : PC7 PC6 */
  GPIO_InitStruct.Pin = GPIO_PIN_7|GPIO_PIN_6;
  GPIO_InitStruct.Mode = GPIO_MODE_AF_PP;
  GPIO_InitStruct.Pull = GPIO_NOPULL;
  GPIO_InitStruct.Speed = GPIO_SPEED_FREQ_VERY_HIGH;
  GPIO_InitStruct.Alternate = GPIO_AF8_USART6;
  HAL_GPIO_Init(GPIOC, &GPIO_InitStruct);

  /*Configure GPIO pin : ULPI_NXT_Pin */
  GPIO_InitStruct.Pin = ULPI_NXT_Pin;
  GPIO_InitStruct.Mode = GPIO_MODE_AF_PP;
  GPIO_InitStruct.Pull = GPIO_NOPULL;
  GPIO_InitStruct.Speed = GPIO_SPEED_FREQ_VERY_HIGH;
  GPIO_InitStruct.Alternate = GPIO_AF10_OTG_HS;
  HAL_GPIO_Init(ULPI_NXT_GPIO_Port, &GPIO_InitStruct);

  /*Configure GPIO pins : BP_JOYSTICK_Pin RMII_RXER_Pin */
  GPIO_InitStruct.Pin = BP_JOYSTICK_Pin|RMII_RXER_Pin;
  GPIO_InitStruct.Mode = GPIO_MODE_INPUT;
  GPIO_InitStruct.Pull = GPIO_NOPULL;
  HAL_GPIO_Init(GPIOG, &GPIO_InitStruct);

  /*Configure GPIO pin : PF7 */
  GPIO_InitStruct.Pin = GPIO_PIN_7;
  GPIO_InitStruct.Mode = GPIO_MODE_AF_PP;
  GPIO_InitStruct.Pull = GPIO_NOPULL;
  GPIO_InitStruct.Speed = GPIO_SPEED_FREQ_VERY_HIGH;
  GPIO_InitStruct.Alternate = GPIO_AF8_UART7;
  HAL_GPIO_Init(GPIOF, &GPIO_InitStruct);

  /*Configure GPIO pins : PF10 PF9 PF8 */
  GPIO_InitStruct.Pin = GPIO_PIN_10|GPIO_PIN_9|GPIO_PIN_8;
  GPIO_InitStruct.Mode = GPIO_MODE_ANALOG;
  GPIO_InitStruct.Pull = GPIO_NOPULL;
  HAL_GPIO_Init(GPIOF, &GPIO_InitStruct);

  /*Configure GPIO pins : ULPI_STP_Pin ULPI_DIR_Pin */
  GPIO_InitStruct.Pin = ULPI_STP_Pin|ULPI_DIR_Pin;
  GPIO_InitStruct.Mode = GPIO_MODE_AF_PP;
  GPIO_InitStruct.Pull = GPIO_NOPULL;
  GPIO_InitStruct.Speed = GPIO_SPEED_FREQ_VERY_HIGH;
  GPIO_InitStruct.Alternate = GPIO_AF10_OTG_HS;
  HAL_GPIO_Init(GPIOC, &GPIO_InitStruct);

  /*Configure GPIO pin : EXT_RST_Pin */
  GPIO_InitStruct.Pin = EXT_RST_Pin;
  GPIO_InitStruct.Mode = GPIO_MODE_OUTPUT_PP;
  GPIO_InitStruct.Pull = GPIO_NOPULL;
  GPIO_InitStruct.Speed = GPIO_SPEED_FREQ_LOW;
  HAL_GPIO_Init(EXT_RST_GPIO_Port, &GPIO_InitStruct);

  /*Configure GPIO pins : PA0 PA4 */
  GPIO_InitStruct.Pin = GPIO_PIN_0|GPIO_PIN_4;
  GPIO_InitStruct.Mode = GPIO_MODE_ANALOG;
  GPIO_InitStruct.Pull = GPIO_NOPULL;
  HAL_GPIO_Init(GPIOA, &GPIO_InitStruct);

  /*Configure GPIO pins : LCD_SCL_Pin LCD_SDA_Pin */
  GPIO_InitStruct.Pin = LCD_SCL_Pin|LCD_SDA_Pin;
  GPIO_InitStruct.Mode = GPIO_MODE_AF_OD;
  GPIO_InitStruct.Pull = GPIO_PULLUP;
  GPIO_InitStruct.Speed = GPIO_SPEED_FREQ_VERY_HIGH;
  GPIO_InitStruct.Alternate = GPIO_AF4_I2C3;
  HAL_GPIO_Init(GPIOH, &GPIO_InitStruct);

  /*Configure GPIO pins : ULPI_CLK_Pin ULPI_D0_Pin */
  GPIO_InitStruct.Pin = ULPI_CLK_Pin|ULPI_D0_Pin;
  GPIO_InitStruct.Mode = GPIO_MODE_AF_PP;
  GPIO_InitStruct.Pull = GPIO_NOPULL;
  GPIO_InitStruct.Speed = GPIO_SPEED_FREQ_VERY_HIGH;
  GPIO_InitStruct.Alternate = GPIO_AF10_OTG_HS;
  HAL_GPIO_Init(GPIOA, &GPIO_InitStruct);

  /*Configure GPIO pins : PB14 PB15 */
  GPIO_InitStruct.Pin = GPIO_PIN_14|GPIO_PIN_15;
  GPIO_InitStruct.Mode = GPIO_MODE_AF_PP;
  GPIO_InitStruct.Pull = GPIO_NOPULL;
  GPIO_InitStruct.Speed = GPIO_SPEED_FREQ_VERY_HIGH;
  GPIO_InitStruct.Alternate = GPIO_AF5_SPI2;
  HAL_GPIO_Init(GPIOB, &GPIO_InitStruct);

}

void StartDefaultTask(void const * argument)
{
  /* init code for LWIP */
  MX_LWIP_Init();
  /* USER CODE BEGIN 5 */

  init();

  /* Infinite loop */
  for(;;)
  {
	HAL_GPIO_TogglePin(LED13_GPIO_Port, LED13_Pin);
    osDelay(500);
  }

  /* USER CODE END 5 */
}

void displayer_task_fn(void const * argument)
{
  /* USER CODE BEGIN displayer_task_fn */

  /* Infinite loop */
  for(;;)
  {
    displayerHandler();
  }

  /* USER CODE END displayer_task_fn */
}

void logic_task_fn(void const * argument)
{
  /* USER CODE BEGIN logic_task_fn */

  /* Infinite loop */
  for(;;)
  {
    logicHandler();
  }

  /* USER CODE END logic_task_fn */
}

 /**
  * @brief  Period elapsed callback in non blocking mode
  * @note   This function is called  when TIM6 interrupt took place, inside
  * HAL_TIM_IRQHandler(). It makes a direct call to HAL_IncTick() to increment
  * a global variable "uwTick" used as application time base.
  * @param  htim : TIM handle
  * @retval None
  */
void HAL_TIM_PeriodElapsedCallback(TIM_HandleTypeDef *htim)
{
  if (htim->Instance == TIM6) {
    HAL_IncTick();
  }
}

void Error_Handler(void)
{
  __disable_irq();
  while (1)
  {
  }
}

/************************ (C) COPYRIGHT STMicroelectronics *****END OF FILE****/
